# STM32F410C8T3 register map
File version: 1.0
Registers are 32-bit, access not given, reset 0x0 unless marked. A register's access mark holds for its fields unless they carry their own. Offsets are from the block's base; [hi:lo] are bit positions; {n}, {i} and the like mark numbered series.

## ADC1
Base 0x40012000
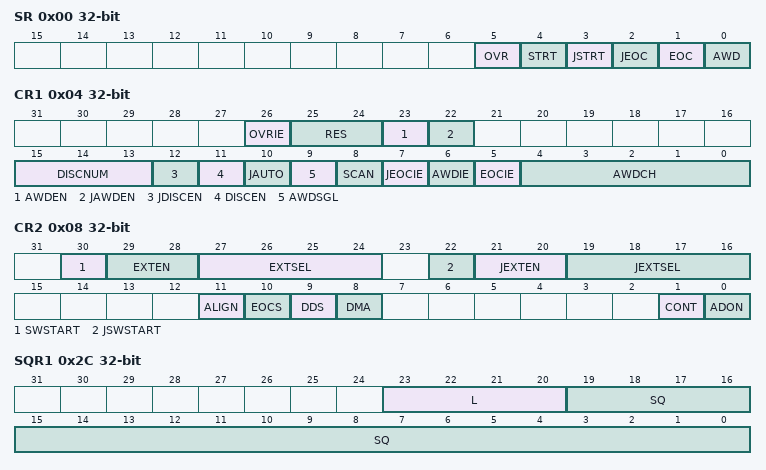
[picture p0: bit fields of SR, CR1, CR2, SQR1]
0x00 SR
  [5] OVR, [4] STRT, [3] JSTRT, [2] JEOC, [1] EOC, [0] AWD
0x04 CR1
  [26] OVRIE, [25:24] RES, [23] AWDEN, [22] JAWDEN, [15:13] DISCNUM, [12] JDISCEN, [11] DISCEN, [10] JAUTO, [9] AWDSGL, [8] SCAN, [7] JEOCIE, [6] AWDIE, [5] EOCIE, [4:0] AWDCH
0x08 CR2
  [30] SWSTART, [29:28] EXTEN, [27:24] EXTSEL, [22] JSWSTART, [21:20] JEXTEN, [19:16] JEXTSEL, [11] ALIGN, [10] EOCS, [9] DDS, [8] DMA, [1] CONT, [0] ADON
0x0C SMPR1
  [31:0] SMP
0x10 SMPR2
  [31:0] SMP
{0x10+4i} JOFR{i} (i=1..4)
  [11:0] JOFFSET{i}
0x24 HTR
  [11:0] HT
0x28 LTR
  [11:0] LT
0x2C SQR1
  [23:20] L, [19:0] SQ
0x30 SQR2
  [29:0] SQ
0x34 SQR3
  [29:0] SQ
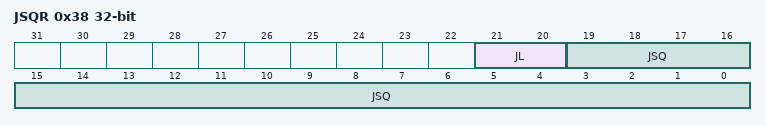
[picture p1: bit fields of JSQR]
0x38 JSQR
  [21:20] JL, [19:0] JSQ
{0x38+4i} JDR{i} (i=1..4)
  [15:0] JDATA
0x4C DR
  [15:0] DATA

## SYSCFG
Base 0x40013800
0x00 MEMRMP
  [1:0] MEM_MODE
0x04 PMC
{0x4+4i} EXTICR{i} (i=1..4)
0x1C CFGR2
0x20 CMPCR
0x24 CFGR

## EXTI
Base 0x40013C00
0x00 IMR
0x04 EMR
0x08 RTSR
0x0C FTSR
0x10 SWIER
0x14 PR

## TIM9
Base 0x40014000
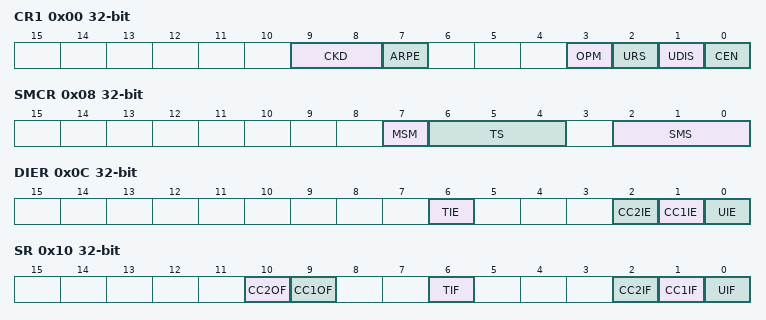
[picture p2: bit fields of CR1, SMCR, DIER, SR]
0x00 CR1
  [9:8] CKD, [7] ARPE, [3] OPM, [2] URS, [1] UDIS, [0] CEN
0x08 SMCR
  [7] MSM, [6:4] TS, [2:0] SMS
0x0C DIER
  [6] TIE, [2] CC2IE, [1] CC1IE, [0] UIE
0x10 SR
  [10] CC2OF, [9] CC1OF, [6] TIF, [2] CC2IF, [1] CC1IF, [0] UIF
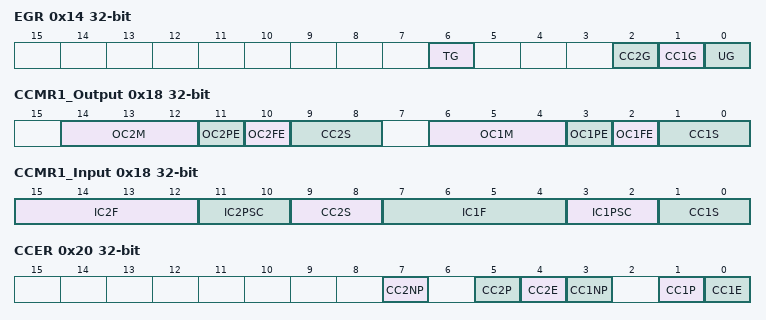
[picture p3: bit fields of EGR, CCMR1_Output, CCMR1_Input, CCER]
0x14 EGR
  [6] TG, [2] CC2G, [1] CC1G, [0] UG
0x18 CCMR1_Output
  [14:12] OC2M, [11] OC2PE, [10] OC2FE, [9:8] CC2S, [6:4] OC1M, [3] OC1PE, [2] OC1FE, [1:0] CC1S
0x18 CCMR1_Input
  [15:12] IC2F, [11:10] IC2PSC, [9:8] CC2S, [7:4] IC1F, [3:2] IC1PSC, [1:0] CC1S
0x20 CCER
  [7] CC2NP, [5] CC2P, [4] CC2E, [3] CC1NP, [1] CC1P, [0] CC1E
0x24 CNT
  [15:0] CNT
0x28 PSC
  [15:0] PSC
0x2C ARR
  [15:0] ARR
0x34 CCR1
  [15:0] CCR1
0x38 CCR2

## TIM11
Base 0x40014800
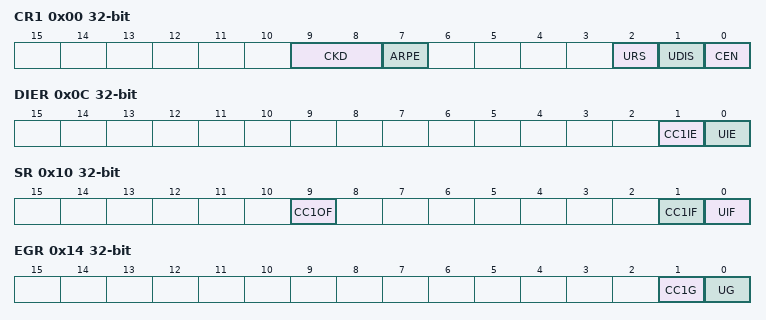
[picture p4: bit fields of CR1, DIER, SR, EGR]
0x00 CR1
  [9:8] CKD, [7] ARPE, [2] URS, [1] UDIS, [0] CEN
0x08 SMCR
0x0C DIER
  [1] CC1IE, [0] UIE
0x10 SR
  [9] CC1OF, [1] CC1IF, [0] UIF
0x14 EGR
  [1] CC1G, [0] UG
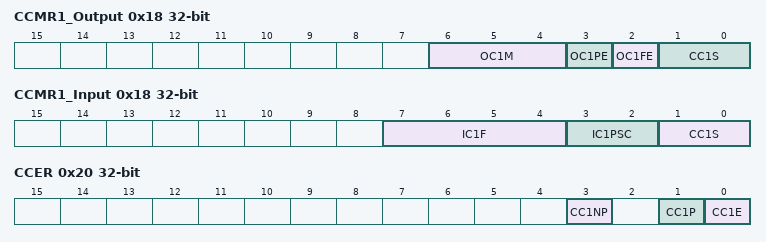
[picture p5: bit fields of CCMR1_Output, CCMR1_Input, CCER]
0x18 CCMR1_Output
  [6:4] OC1M, [3] OC1PE, [2] OC1FE, [1:0] CC1S
0x18 CCMR1_Input
  [7:4] IC1F, [3:2] IC1PSC, [1:0] CC1S
0x20 CCER
  [3] CC1NP, [1] CC1P, [0] CC1E
0x24 CNT
  [15:0] CNT
0x28 PSC
  [15:0] PSC
0x2C ARR
  [15:0] ARR
0x34 CCR1
  [15:0] CCR1
0x50 OR
  [1:0] TI1_RMP

## GPIOA
Base 0x40020000
Same registers: GPIOB 0x40020400, GPIOC 0x40020800, GPIOH 0x40021C00
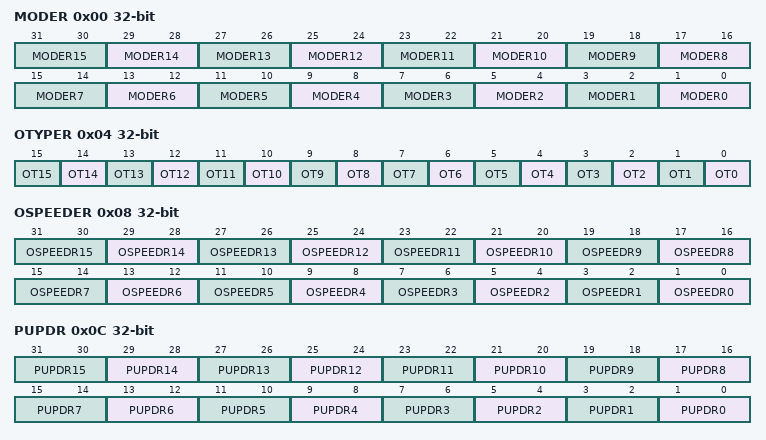
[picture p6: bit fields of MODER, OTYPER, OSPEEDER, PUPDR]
0x00 MODER
  [2n+1:2n] MODER{n} (n=0..15)
0x04 OTYPER
  [n] OT{n} (n=0..15)
0x08 OSPEEDER
  [2n+1:2n] OSPEEDR{n} (n=0..15)
0x0C PUPDR
  [2n+1:2n] PUPDR{n} (n=0..15)
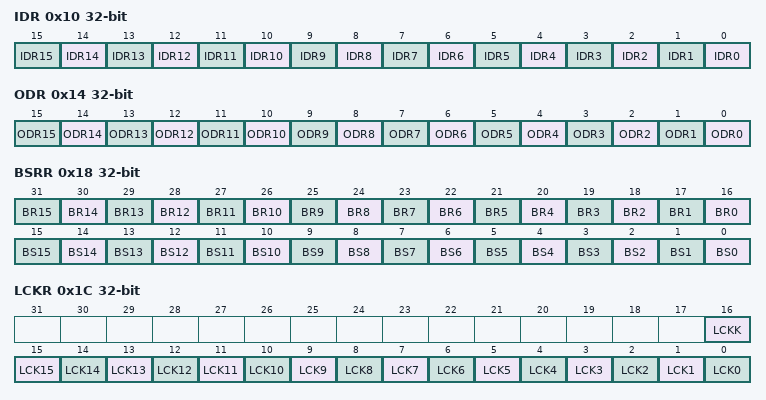
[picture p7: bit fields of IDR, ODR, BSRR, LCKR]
0x10 IDR
  [n] IDR{n} (n=0..15)
0x14 ODR
  [n] ODR{n} (n=0..15)
0x18 BSRR
  [n+16] BR{n} (n=0..15), [n] BS{n} (n=0..15)
0x1C LCKR
  [16] LCKK, [n] LCK{n} (n=0..15)
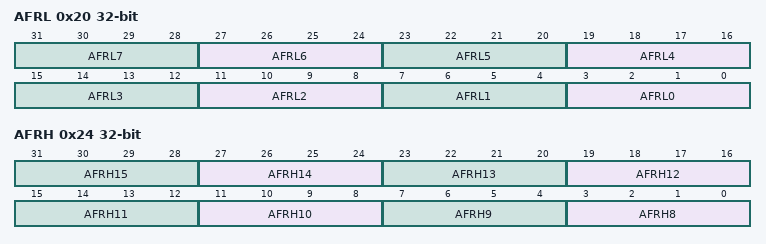
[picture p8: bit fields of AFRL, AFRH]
0x20 AFRL
  [4n+3:4n] AFRL{n} (n=0..7)
0x24 AFRH
  [4n-29:4n-32] AFRH{n} (n=8..15)

## LPTIM1
Base 0x40022400
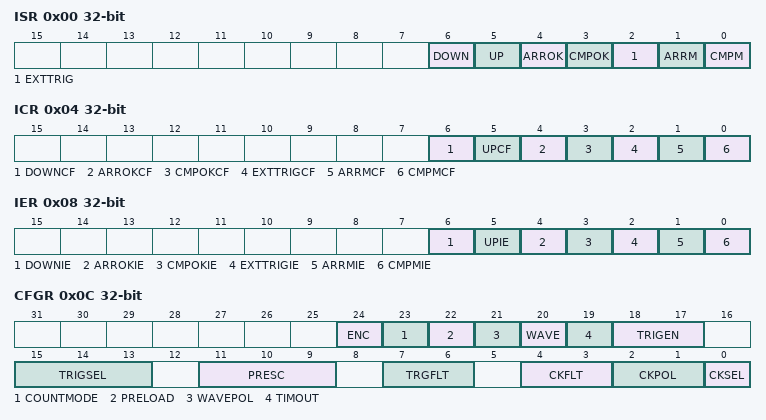
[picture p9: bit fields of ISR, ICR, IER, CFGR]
0x00 ISR
  [6] DOWN, [5] UP, [4] ARROK, [3] CMPOK, [2] EXTTRIG, [1] ARRM, [0] CMPM
0x04 ICR
  [6] DOWNCF, [5] UPCF, [4] ARROKCF, [3] CMPOKCF, [2] EXTTRIGCF, [1] ARRMCF, [0] CMPMCF
0x08 IER
  [6] DOWNIE, [5] UPIE, [4] ARROKIE, [3] CMPOKIE, [2] EXTTRIGIE, [1] ARRMIE, [0] CMPMIE
0x0C CFGR
  [24] ENC, [23] COUNTMODE, [22] PRELOAD, [21] WAVEPOL, [20] WAVE, [19] TIMOUT, [18:17] TRIGEN, [15:13] TRIGSEL, [11:9] PRESC, [7:6] TRGFLT, [4:3] CKFLT, [2:1] CKPOL, [0] CKSEL
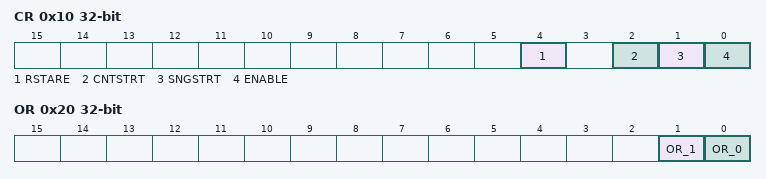
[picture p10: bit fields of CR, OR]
0x10 CR
  [4] RSTARE, [2] CNTSTRT, [1] SNGSTRT, [0] ENABLE
0x14 CMP
  [15:0] CMP
0x18 ARR
  [15:0] ARR
0x1C CNT
  [15:0] CNT
0x20 OR
  [1] OR_1, [0] OR_0

## CRC
Base 0x40023000
0x00 DR
  [31:0] DATA
0x04 IDR
  [7:0] DATA
0x08 CR
  [0] RESET

## RCC
Base 0x40023800
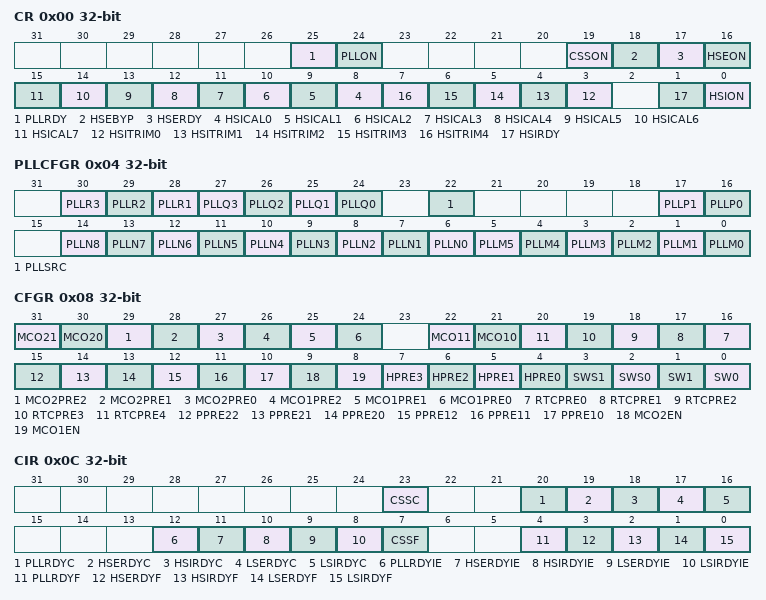
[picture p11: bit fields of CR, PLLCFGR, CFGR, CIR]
0x00 CR
  [25] PLLRDY, [24] PLLON, [19] CSSON, [18] HSEBYP, [17] HSERDY, [16] HSEON, [n+8] HSICAL{n} (n=0..7), [n+3] HSITRIM{n} (n=0..4), [1] HSIRDY, [0] HSION
0x04 PLLCFGR
  [30] PLLR3, [29] PLLR2, [28] PLLR1, [n+24] PLLQ{n} (n=0..3), [22] PLLSRC, [17] PLLP1, [16] PLLP0, [n+6] PLLN{n} (n=0..8), [n] PLLM{n} (n=0..5)
0x08 CFGR
  [31] MCO21, [30] MCO20, [29] MCO2PRE2, [28] MCO2PRE1, [27] MCO2PRE0, [26] MCO1PRE2, [25] MCO1PRE1, [24] MCO1PRE0, [22] MCO11, [21] MCO10, [n+16] RTCPRE{n} (n=0..4), [15] PPRE22, [14] PPRE21, [13] PPRE20, [12] PPRE12, [11] PPRE11, [10] PPRE10, [9] MCO2EN, [8] MCO1EN, [n+4] HPRE{n} (n=0..3), [3] SWS1, [2] SWS0, [1] SW1, [0] SW0
0x0C CIR
  [23] CSSC, [20] PLLRDYC, [19] HSERDYC, [18] HSIRDYC, [17] LSERDYC, [16] LSIRDYC, [12] PLLRDYIE, [11] HSERDYIE, [10] HSIRDYIE, [9] LSERDYIE, [8] LSIRDYIE, [7] CSSF, [4] PLLRDYF, [3] HSERDYF, [2] HSIRDYF, [1] LSERDYF, [0] LSIRDYF
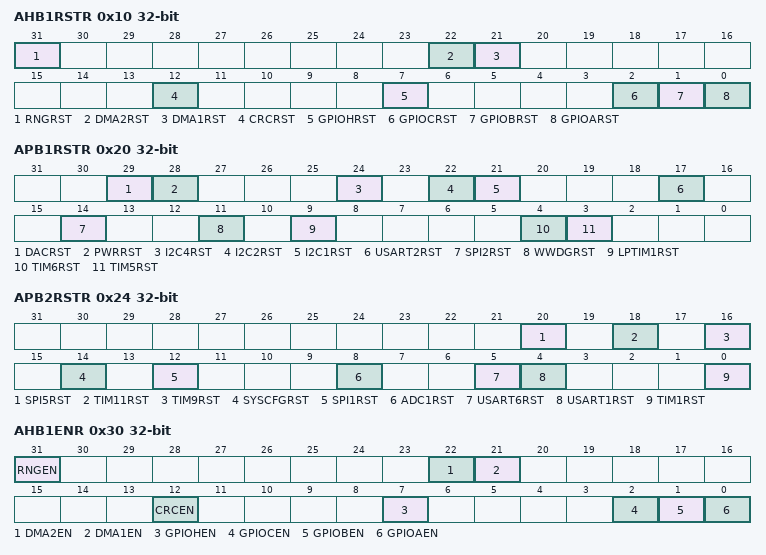
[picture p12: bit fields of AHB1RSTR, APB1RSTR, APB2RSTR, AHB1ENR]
0x10 AHB1RSTR
  [31] RNGRST, [22] DMA2RST, [21] DMA1RST, [12] CRCRST, [7] GPIOHRST, [2] GPIOCRST, [1] GPIOBRST, [0] GPIOARST
0x20 APB1RSTR
  [29] DACRST, [28] PWRRST, [24] I2C4RST, [22] I2C2RST, [21] I2C1RST, [17] USART2RST, [14] SPI2RST, [11] WWDGRST, [9] LPTIM1RST, [4] TIM6RST, [3] TIM5RST
0x24 APB2RSTR
  [20] SPI5RST, [18] TIM11RST, [16] TIM9RST, [14] SYSCFGRST, [12] SPI1RST, [8] ADC1RST, [5] USART6RST, [4] USART1RST, [0] TIM1RST
0x30 AHB1ENR
  [31] RNGEN, [22] DMA2EN, [21] DMA1EN, [12] CRCEN, [7] GPIOHEN, [2] GPIOCEN, [1] GPIOBEN, [0] GPIOAEN
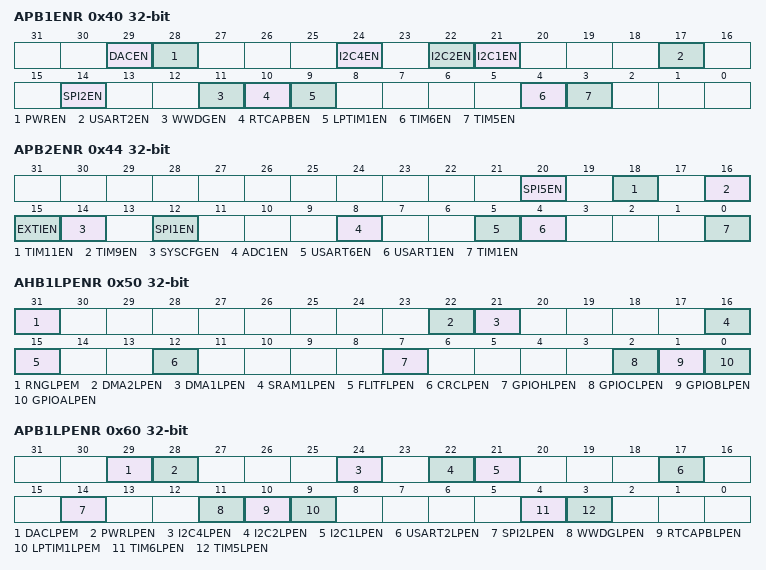
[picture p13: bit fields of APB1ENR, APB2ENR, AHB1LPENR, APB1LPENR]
0x40 APB1ENR
  [29] DACEN, [28] PWREN, [24] I2C4EN, [22] I2C2EN, [21] I2C1EN, [17] USART2EN, [14] SPI2EN, [11] WWDGEN, [10] RTCAPBEN, [9] LPTIM1EN, [4] TIM6EN, [3] TIM5EN
0x44 APB2ENR
  [20] SPI5EN, [18] TIM11EN, [16] TIM9EN, [15] EXTIEN, [14] SYSCFGEN, [12] SPI1EN, [8] ADC1EN, [5] USART6EN, [4] USART1EN, [0] TIM1EN
0x50 AHB1LPENR
  [31] RNGLPEM, [22] DMA2LPEN, [21] DMA1LPEN, [16] SRAM1LPEN, [15] FLITFLPEN, [12] CRCLPEN, [7] GPIOHLPEN, [2] GPIOCLPEN, [1] GPIOBLPEN, [0] GPIOALPEN
0x60 APB1LPENR
  [29] DACLPEM, [28] PWRLPEN, [24] I2C4LPEN, [22] I2C2LPEN, [21] I2C1LPEN, [17] USART2LPEN, [14] SPI2LPEN, [11] WWDGLPEN, [10] RTCAPBLPEN, [9] LPTIM1LPEM, [4] TIM6LPEN, [3] TIM5LPEN
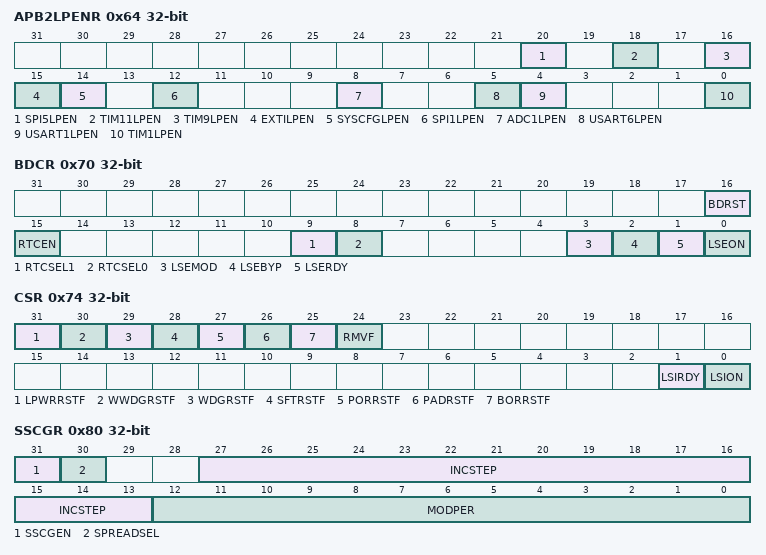
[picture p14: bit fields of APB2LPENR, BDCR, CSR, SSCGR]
0x64 APB2LPENR
  [20] SPI5LPEN, [18] TIM11LPEN, [16] TIM9LPEN, [15] EXTILPEN, [14] SYSCFGLPEN, [12] SPI1LPEN, [8] ADC1LPEN, [5] USART6LPEN, [4] USART1LPEN, [0] TIM1LPEN
0x70 BDCR
  [16] BDRST, [15] RTCEN, [9] RTCSEL1, [8] RTCSEL0, [3] LSEMOD, [2] LSEBYP, [1] LSERDY, [0] LSEON
0x74 CSR
  [31] LPWRRSTF, [30] WWDGRSTF, [29] WDGRSTF, [28] SFTRSTF, [27] PORRSTF, [26] PADRSTF, [25] BORRSTF, [24] RMVF, [1] LSIRDY, [0] LSION
0x80 SSCGR
  [31] SSCGEN, [30] SPREADSEL, [27:13] INCSTEP, [12:0] MODPER
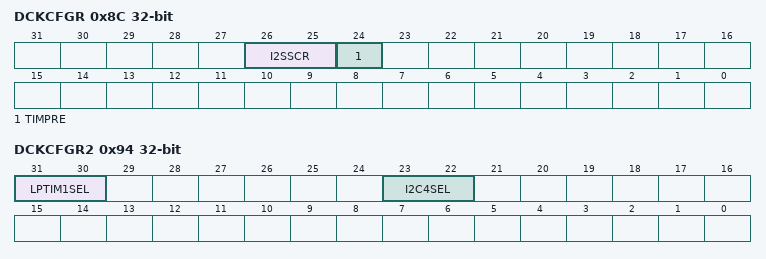
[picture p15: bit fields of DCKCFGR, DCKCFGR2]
0x8C DCKCFGR
  [26:25] I2SSCR, [24] TIMPRE
0x94 DCKCFGR2
  [31:30] LPTIM1SEL, [23:22] I2C4SEL

## FLASH
Base 0x40023C00
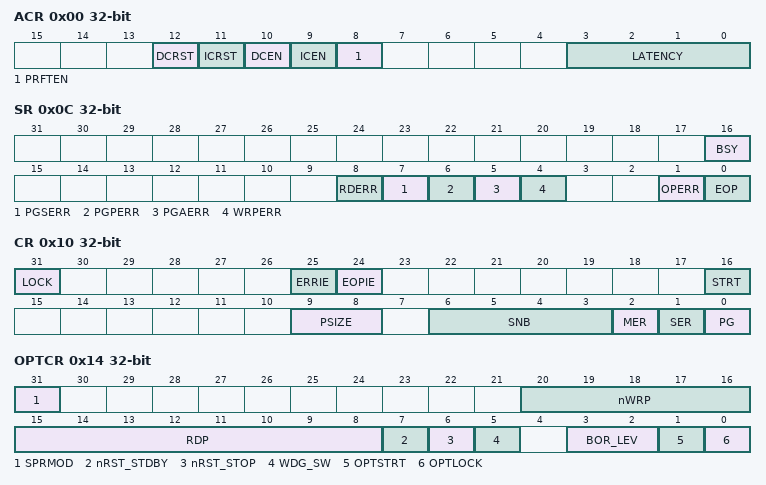
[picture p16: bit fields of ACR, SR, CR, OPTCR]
0x00 ACR
  [12] DCRST, [11] ICRST, [10] DCEN, [9] ICEN, [8] PRFTEN, [3:0] LATENCY
0x04 KEYR
  [31:0] KEY
0x08 OPTKEYR
0x0C SR
  [16] BSY, [8] RDERR, [7] PGSERR, [6] PGPERR, [5] PGAERR, [4] WRPERR, [1] OPERR, [0] EOP
0x10 CR
  [31] LOCK, [25] ERRIE, [24] EOPIE, [16] STRT, [9:8] PSIZE, [6:3] SNB, [2] MER, [1] SER, [0] PG
0x14 OPTCR
  [31] SPRMOD, [20:16] nWRP, [15:8] RDP, [7] nRST_STDBY, [6] nRST_STOP, [5] WDG_SW, [3:2] BOR_LEV, [1] OPTSTRT, [0] OPTLOCK

## DMA1
Base 0x40026000
Same registers: DMA2 0x40026400
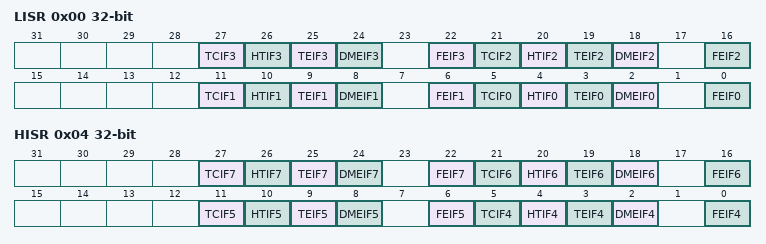
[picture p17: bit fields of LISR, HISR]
0x00 LISR
  [27] TCIF3, [26] HTIF3, [25] TEIF3, [24] DMEIF3, [22] FEIF3, [21] TCIF2, [20] HTIF2, [19] TEIF2, [18] DMEIF2, [16] FEIF2, [11] TCIF1, [10] HTIF1, [9] TEIF1, [8] DMEIF1, [6] FEIF1, [5] TCIF0, [4] HTIF0, [3] TEIF0, [2] DMEIF0, [0] FEIF0
0x04 HISR
  [27] TCIF7, [26] HTIF7, [25] TEIF7, [24] DMEIF7, [22] FEIF7, [21] TCIF6, [20] HTIF6, [19] TEIF6, [18] DMEIF6, [16] FEIF6, [11] TCIF5, [10] HTIF5, [9] TEIF5, [8] DMEIF5, [6] FEIF5, [5] TCIF4, [4] HTIF4, [3] TEIF4, [2] DMEIF4, [0] FEIF4
0x08 LIFCR
  [27] CTCIF3, [26] CHTIF3, [25] TEIF3, [24] CDMEIF3, [22] CFEIF3, [21] CTCIF2, [20] CHTIF2, [19] CTEIF2, [18] CDMEIF2, [16] CFEIF2, [11] CTCIF1, [10] CHTIF1, [9] CTEIF1, [8] CDMEIF1, [6] CFEIF1, [5] CTCIF0, [4] CHTIF0, [3] CTEIF0, [2] CDMEIF0, [0] CFEIF0
0x0C HIFCR
  [27] CTCIF7, [26] CHTIF7, [25] CTEIF7, [24] CDMEIF7, [22] CFEIF7, [21] CTCIF6, [20] CHTIF6, [19] CTEIF6, [18] CDMEIF6, [16] CFEIF6, [11] CTCIF5, [10] CHTIF5, [9] CTEIF5, [8] CDMEIF5, [6] CFEIF5, [5] CTCIF4, [4] CHTIF4, [3] CTEIF4, [2] CDMEIF4, [0] CFEIF4
{0x10+0x18*i} S{i}CR (i=0..7)
  [27:25] CHSEL, [24:23] MBURST, [22:21] PBURST, [19] CT, [18] DBM, [17:16] PL, [15] PINCOS, [14:13] MSIZE, [12:11] PSIZE, [10] MINC, [9] PINC, [8] CIRC, [7:6] DIR, [5] PFCTRL, [4] TCIE, [3] HTIE, [2] TEIE, [1] DMEIE, [0] EN
{0x14+0x18*i} S{i}NDTR (i=0..7)
  [15:0] NDT
{0x18+0x18*i} S{i}PAR (i=0..7)
  [31:0] PA
{0x1C+0x18*i} S{i}M0AR (i=0..7)
  [31:0] M0A
{0x20+0x18*i} S{i}M1AR (i=0..7)
  [31:0] M1A
{0x24+0x18*i} S{i}FCR (i=0..7)
  [7] FEIE, [5:3] FS, [2] DMDIS, [1:0] FTH

## RNG
Base 0x40080000
0x00 CR
  [5] CED, [3] IE, [2] RNGEN
0x04 SR
  [6] SEIS, [5] CEIS, [2] SECS, [1] CECS, [0] DRDY
0x08 DR
  [31:0] RNDATA
